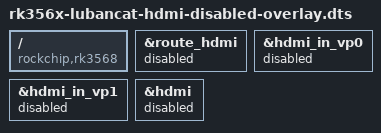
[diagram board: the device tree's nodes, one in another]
/dts-v1/;
/plugin/;

/ {
	compatible = "rockchip,rk3568";

	fragment@0 {
		target = <&route_hdmi>;

		__overlay__ {
			status = "disabled";
		};
	};

	fragment@1 {
		target = <&hdmi_in_vp0>;

		__overlay__ {
			status = "disabled";
		};
	};

	fragment@2 {
		target = <&hdmi_in_vp1>;

		__overlay__ {
			status = "disabled";
		};
	};

	fragment@3 {
		target = <&hdmi>;

		__overlay__ {
			status = "disabled";
		};
	};
};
